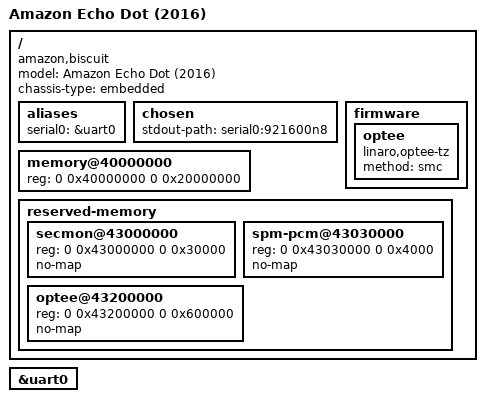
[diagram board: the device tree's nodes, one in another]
// SPDX-License-Identifier: GPL-2.0-only OR MIT
/*
 * Copyright (c) 2026 Ben Grisdale <bengris32@protonmail.ch>
 */

/dts-v1/;
#include "mt8163.dtsi"

/ {
	model = "Amazon Echo Dot (2016)";
	compatible = "amazon,biscuit", "mediatek,mt8163";
	chassis-type = "embedded";

	aliases {
		serial0 = &uart0;
	};

	chosen {
		stdout-path = "serial0:921600n8";
	};

	firmware {
		optee {
			compatible = "linaro,optee-tz";
			method = "smc";
		};
	};

	memory@40000000 {
		device_type = "memory";
		reg = <0 0x40000000 0 0x20000000>;
	};

	reserved-memory {
		ranges;
		#address-cells = <2>;
		#size-cells = <2>;

		/* 192 KiB reserved for ARM Trusted Firmware (BL31) */
		secmon@43000000 {
			reg = <0 0x43000000 0 0x30000>;
			no-map;
		};

		/* 16 KiB reserved for SPM firmware */
		spm-pcm@43030000 {
			reg = <0 0x43030000 0 0x4000>;
			no-map;
		};

		/*
		 * 6 MiB reserved for OP-TEE (BL32)
		 * +-----------------------+ 0x4380_0000
		 * |      SHMEM 2MiB       |
		 * +-----------------------+ 0x4360_0000
		 * |     TZDRAM 4MiB       |
		 * +-----------------------+ 0x4320_0000
		 */
		optee@43200000 {
			reg = <0 0x43200000 0 0x600000>;
			no-map;
		};
	};
};

&uart0 {
	status = "okay";
};
